# ESP32 register map
Vendor: ESPRESSIF SYSTEMS (SHANGHAI) CO., LTD.; Series: ESP32 Series; File version: 17
CPU: Xtensa LX6 r0p0, little endian, no MPU, FPU, 0 interrupt priority bits
Address unit: 32 bits
Registers are 32-bit, read-write, reset 0x0 unless marked. A register's access mark holds for its fields unless they carry their own. Offsets are from the block's base; [hi:lo] are bit positions; {n}, {i} and the like mark numbered series; 'fields as' and 'values as' point back to an identical list.

## MCPWM0 — Motor Control Pulse-Width Modulation 0
Base 0x3FF5E000
Same registers: MCPWM1 0x3FF6C000
0x00 CLK_CFG
  [7:0] CLK_PRESCALE
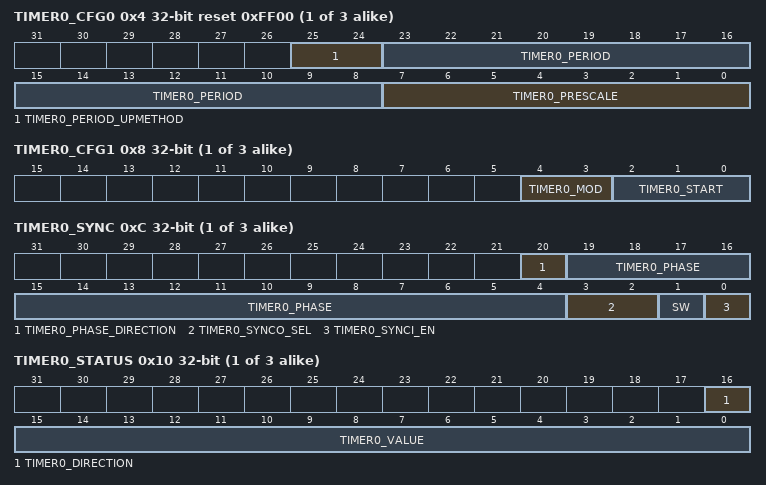
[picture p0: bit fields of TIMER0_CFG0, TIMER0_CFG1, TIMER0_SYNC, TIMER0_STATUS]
{0x4+0x10*i} TIMER{i}_CFG0 reset 0xFF00 (i=0..2)
  [25:24] TIMER{i}_PERIOD_UPMETHOD, [23:8] TIMER{i}_PERIOD, [7:0] TIMER{i}_PRESCALE
{0x8+0x10*i} TIMER{i}_CFG1 (i=0..2)
  [4:3] TIMER{i}_MOD, [2:0] TIMER{i}_START
{0xC+0x10*i} TIMER{i}_SYNC (i=0..2)
  [20] TIMER{i}_PHASE_DIRECTION, [19:4] TIMER{i}_PHASE, [3:2] TIMER{i}_SYNCO_SEL, [1] SW, [0] TIMER{i}_SYNCI_EN
{0x10+0x10*i} TIMER{i}_STATUS ro (i=0..2)
  [16] TIMER{i}_DIRECTION, [15:0] TIMER{i}_VALUE
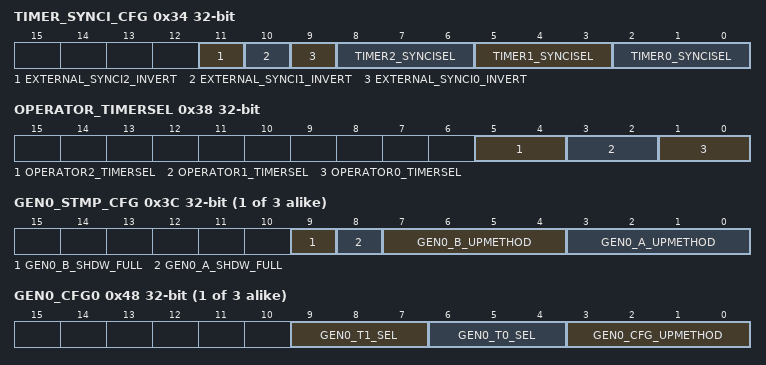
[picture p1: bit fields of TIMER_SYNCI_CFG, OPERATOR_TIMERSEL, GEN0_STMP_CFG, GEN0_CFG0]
0x34 TIMER_SYNCI_CFG
  [11] EXTERNAL_SYNCI2_INVERT, [10] EXTERNAL_SYNCI1_INVERT, [9] EXTERNAL_SYNCI0_INVERT, [8:6] TIMER2_SYNCISEL, [5:3] TIMER1_SYNCISEL, [2:0] TIMER0_SYNCISEL
0x38 OPERATOR_TIMERSEL
  [5:4] OPERATOR2_TIMERSEL, [3:2] OPERATOR1_TIMERSEL, [1:0] OPERATOR0_TIMERSEL
{0x3C+0x38*i} GEN{i}_STMP_CFG (i=0..2)
  [9] GEN{i}_B_SHDW_FULL, [8] GEN{i}_A_SHDW_FULL, [7:4] GEN{i}_B_UPMETHOD, [3:0] GEN{i}_A_UPMETHOD
{0x40+0x38*i} GEN{i}_TSTMP_A (i=0..2)
  [15:0] GEN{i}_A
{0x44+0x38*i} GEN{i}_TSTMP_B (i=0..2)
  [15:0] GEN{i}_B
{0x48+0x38*i} GEN{i}_CFG0 (i=0..2)
  [9:7] GEN{i}_T1_SEL, [6:4] GEN{i}_T0_SEL, [3:0] GEN{i}_CFG_UPMETHOD
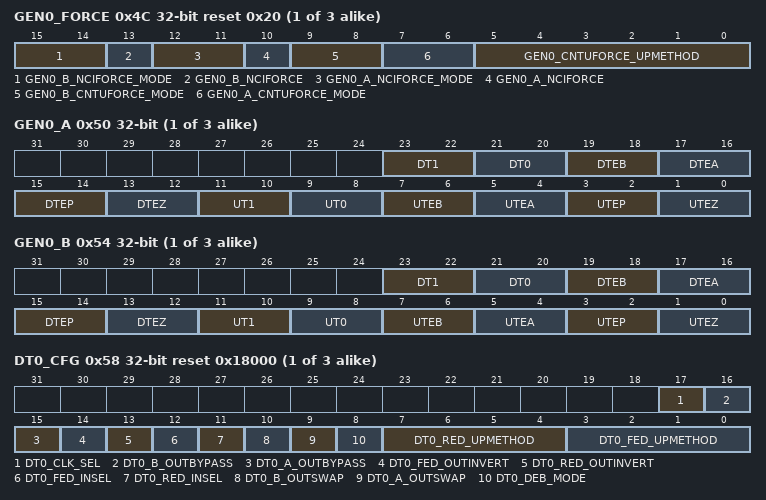
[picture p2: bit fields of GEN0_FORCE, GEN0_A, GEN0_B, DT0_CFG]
{0x4C+0x38*i} GEN{i}_FORCE reset 0x20 (i=0..2)
  [15:14] GEN{i}_B_NCIFORCE_MODE, [13] GEN{i}_B_NCIFORCE, [12:11] GEN{i}_A_NCIFORCE_MODE, [10] GEN{i}_A_NCIFORCE, [9:8] GEN{i}_B_CNTUFORCE_MODE, [7:6] GEN{i}_A_CNTUFORCE_MODE, [5:0] GEN{i}_CNTUFORCE_UPMETHOD
{0x50+0x38*i} GEN{i}_A (i=0..2)
  [23:22] DT1, [21:20] DT0, [19:18] DTEB, [17:16] DTEA, [15:14] DTEP, [13:12] DTEZ, [11:10] UT1, [9:8] UT0, [7:6] UTEB, [5:4] UTEA, [3:2] UTEP, [1:0] UTEZ
{0x54+0x38*i} GEN{i}_B (i=0..2)
  fields as GEN0_A
{0x58+0x38*i} DT{i}_CFG reset 0x18000 (i=0..2)
  [17] DT{i}_CLK_SEL, [16] DT{i}_B_OUTBYPASS, [15] DT{i}_A_OUTBYPASS, [14] DT{i}_FED_OUTINVERT, [13] DT{i}_RED_OUTINVERT, [12] DT{i}_FED_INSEL, [11] DT{i}_RED_INSEL, [10] DT{i}_B_OUTSWAP, [9] DT{i}_A_OUTSWAP, [8] DT{i}_DEB_MODE, [7:4] DT{i}_RED_UPMETHOD, [3:0] DT{i}_FED_UPMETHOD
{0x5C+0x38*i} DT{i}_FED_CFG (i=0..2)
  [15:0] DT{i}_FED
{0x60+0x38*i} DT{i}_RED_CFG (i=0..2)
  [15:0] DT{i}_RED
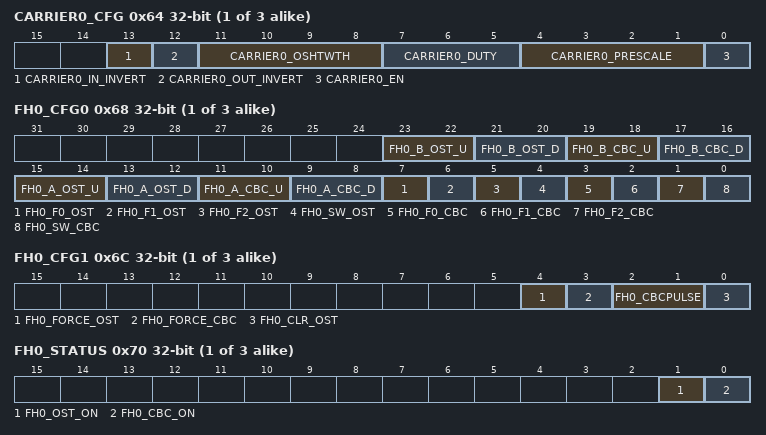
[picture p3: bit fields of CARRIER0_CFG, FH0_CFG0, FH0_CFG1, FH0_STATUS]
{0x64+0x38*i} CARRIER{i}_CFG (i=0..2)
  [13] CARRIER{i}_IN_INVERT, [12] CARRIER{i}_OUT_INVERT, [11:8] CARRIER{i}_OSHTWTH, [7:5] CARRIER{i}_DUTY, [4:1] CARRIER{i}_PRESCALE, [0] CARRIER{i}_EN
{0x68+0x38*i} FH{i}_CFG0 (i=0..2)
  [23:22] FH{i}_B_OST_U, [21:20] FH{i}_B_OST_D, [19:18] FH{i}_B_CBC_U, [17:16] FH{i}_B_CBC_D, [15:14] FH{i}_A_OST_U, [13:12] FH{i}_A_OST_D, [11:10] FH{i}_A_CBC_U, [9:8] FH{i}_A_CBC_D, [7] FH{i}_F0_OST, [6] FH{i}_F1_OST, [5] FH{i}_F2_OST, [4] FH{i}_SW_OST, [3] FH{i}_F0_CBC, [2] FH{i}_F1_CBC, [1] FH{i}_F2_CBC, [0] FH{i}_SW_CBC
{0x6C+0x38*i} FH{i}_CFG1 (i=0..2)
  [4] FH{i}_FORCE_OST, [3] FH{i}_FORCE_CBC, [2:1] FH{i}_CBCPULSE, [0] FH{i}_CLR_OST
{0x70+0x38*i} FH{i}_STATUS ro (i=0..2)
  [1] FH{i}_OST_ON, [0] FH{i}_CBC_ON
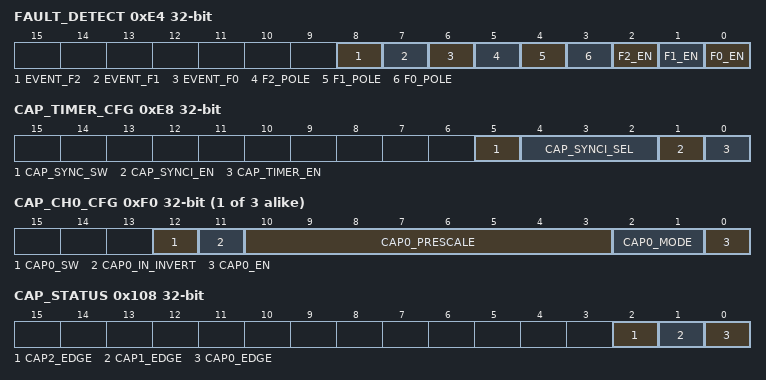
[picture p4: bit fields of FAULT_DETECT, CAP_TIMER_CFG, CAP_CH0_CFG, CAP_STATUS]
0xE4 FAULT_DETECT access per field
  [8] EVENT_F2 ro, [7] EVENT_F1 ro, [6] EVENT_F0 ro, [5] F2_POLE rw, [4] F1_POLE rw, [3] F0_POLE rw, [2] F2_EN rw, [1] F1_EN rw, [0] F0_EN rw
0xE8 CAP_TIMER_CFG access per field
  [5] CAP_SYNC_SW wo, [4:2] CAP_SYNCI_SEL rw, [1] CAP_SYNCI_EN rw, [0] CAP_TIMER_EN rw
0xEC CAP_TIMER_PHASE
{0xF0+4i} CAP_CH{i}_CFG access per field (i=0..2)
  [12] CAP{i}_SW wo, [11] CAP{i}_IN_INVERT rw, [10:3] CAP{i}_PRESCALE rw, [2:1] CAP{i}_MODE rw, [0] CAP{i}_EN rw
{0xFC+4i} CAP_CH{i} ro (i=0..2)
  [31:0] CAP{i}_VALUE
0x108 CAP_STATUS ro
  [2] CAP2_EDGE, [1] CAP1_EDGE, [0] CAP0_EDGE
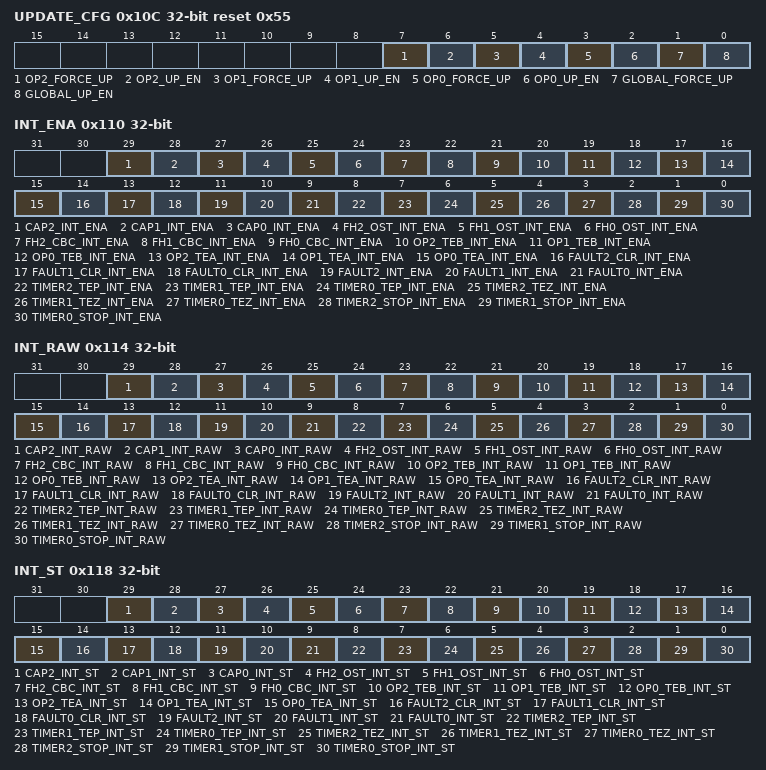
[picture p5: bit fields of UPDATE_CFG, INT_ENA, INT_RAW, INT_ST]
0x10C UPDATE_CFG reset 0x55
  [7] OP2_FORCE_UP, [6] OP2_UP_EN, [5] OP1_FORCE_UP, [4] OP1_UP_EN, [3] OP0_FORCE_UP, [2] OP0_UP_EN, [1] GLOBAL_FORCE_UP, [0] GLOBAL_UP_EN
0x110 INT_ENA
  [29] CAP2_INT_ENA, [28] CAP1_INT_ENA, [27] CAP0_INT_ENA, [26] FH2_OST_INT_ENA, [25] FH1_OST_INT_ENA, [24] FH0_OST_INT_ENA, [23] FH2_CBC_INT_ENA, [22] FH1_CBC_INT_ENA, [21] FH0_CBC_INT_ENA, [20] OP2_TEB_INT_ENA, [19] OP1_TEB_INT_ENA, [18] OP0_TEB_INT_ENA, [17] OP2_TEA_INT_ENA, [16] OP1_TEA_INT_ENA, [15] OP0_TEA_INT_ENA, [14] FAULT2_CLR_INT_ENA, [13] FAULT1_CLR_INT_ENA, [12] FAULT0_CLR_INT_ENA, [11] FAULT2_INT_ENA, [10] FAULT1_INT_ENA, [9] FAULT0_INT_ENA, [8] TIMER2_TEP_INT_ENA, [7] TIMER1_TEP_INT_ENA, [6] TIMER0_TEP_INT_ENA, [5] TIMER2_TEZ_INT_ENA, [4] TIMER1_TEZ_INT_ENA, [3] TIMER0_TEZ_INT_ENA, [2] TIMER2_STOP_INT_ENA, [1] TIMER1_STOP_INT_ENA, [0] TIMER0_STOP_INT_ENA
0x114 INT_RAW ro
  [29] CAP2_INT_RAW, [28] CAP1_INT_RAW, [27] CAP0_INT_RAW, [26] FH2_OST_INT_RAW, [25] FH1_OST_INT_RAW, [24] FH0_OST_INT_RAW, [23] FH2_CBC_INT_RAW, [22] FH1_CBC_INT_RAW, [21] FH0_CBC_INT_RAW, [20] OP2_TEB_INT_RAW, [19] OP1_TEB_INT_RAW, [18] OP0_TEB_INT_RAW, [17] OP2_TEA_INT_RAW, [16] OP1_TEA_INT_RAW, [15] OP0_TEA_INT_RAW, [14] FAULT2_CLR_INT_RAW, [13] FAULT1_CLR_INT_RAW, [12] FAULT0_CLR_INT_RAW, [11] FAULT2_INT_RAW, [10] FAULT1_INT_RAW, [9] FAULT0_INT_RAW, [8] TIMER2_TEP_INT_RAW, [7] TIMER1_TEP_INT_RAW, [6] TIMER0_TEP_INT_RAW, [5] TIMER2_TEZ_INT_RAW, [4] TIMER1_TEZ_INT_RAW, [3] TIMER0_TEZ_INT_RAW, [2] TIMER2_STOP_INT_RAW, [1] TIMER1_STOP_INT_RAW, [0] TIMER0_STOP_INT_RAW
0x118 INT_ST ro
  [29] CAP2_INT_ST, [28] CAP1_INT_ST, [27] CAP0_INT_ST, [26] FH2_OST_INT_ST, [25] FH1_OST_INT_ST, [24] FH0_OST_INT_ST, [23] FH2_CBC_INT_ST, [22] FH1_CBC_INT_ST, [21] FH0_CBC_INT_ST, [20] OP2_TEB_INT_ST, [19] OP1_TEB_INT_ST, [18] OP0_TEB_INT_ST, [17] OP2_TEA_INT_ST, [16] OP1_TEA_INT_ST, [15] OP0_TEA_INT_ST, [14] FAULT2_CLR_INT_ST, [13] FAULT1_CLR_INT_ST, [12] FAULT0_CLR_INT_ST, [11] FAULT2_INT_ST, [10] FAULT1_INT_ST, [9] FAULT0_INT_ST, [8] TIMER2_TEP_INT_ST, [7] TIMER1_TEP_INT_ST, [6] TIMER0_TEP_INT_ST, [5] TIMER2_TEZ_INT_ST, [4] TIMER1_TEZ_INT_ST, [3] TIMER0_TEZ_INT_ST, [2] TIMER2_STOP_INT_ST, [1] TIMER1_STOP_INT_ST, [0] TIMER0_STOP_INT_ST
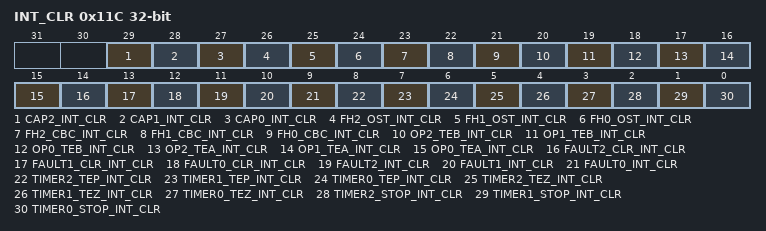
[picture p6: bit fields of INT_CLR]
0x11C INT_CLR wo
  [29] CAP2_INT_CLR, [28] CAP1_INT_CLR, [27] CAP0_INT_CLR, [26] FH2_OST_INT_CLR, [25] FH1_OST_INT_CLR, [24] FH0_OST_INT_CLR, [23] FH2_CBC_INT_CLR, [22] FH1_CBC_INT_CLR, [21] FH0_CBC_INT_CLR, [20] OP2_TEB_INT_CLR, [19] OP1_TEB_INT_CLR, [18] OP0_TEB_INT_CLR, [17] OP2_TEA_INT_CLR, [16] OP1_TEA_INT_CLR, [15] OP0_TEA_INT_CLR, [14] FAULT2_CLR_INT_CLR, [13] FAULT1_CLR_INT_CLR, [12] FAULT0_CLR_INT_CLR, [11] FAULT2_INT_CLR, [10] FAULT1_INT_CLR, [9] FAULT0_INT_CLR, [8] TIMER2_TEP_INT_CLR, [7] TIMER1_TEP_INT_CLR, [6] TIMER0_TEP_INT_CLR, [5] TIMER2_TEZ_INT_CLR, [4] TIMER1_TEZ_INT_CLR, [3] TIMER0_TEZ_INT_CLR, [2] TIMER2_STOP_INT_CLR, [1] TIMER1_STOP_INT_CLR, [0] TIMER0_STOP_INT_CLR
0x120 CLK
  [0] EN
0x124 VERSION reset 0x2107230
  [27:0] DATE
